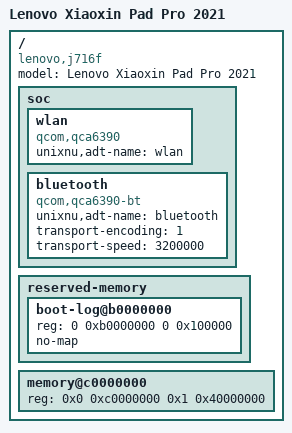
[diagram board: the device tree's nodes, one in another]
// SPDX-License-Identifier: BSD-2-Clause-Patent
// Board-level hardware description for Lenovo TB-J716F.
/dts-v1/;
/include/ "sm8250.dtsi"

/ {
    model = "Lenovo Xiaoxin Pad Pro 2021";
    compatible = "lenovo,j716f", "qcom,kona";

    // Export the radios under /soc (/arm-io in ADT) before launchd evaluates wifid's device-tree condition.
    // WifiProbe owns PCIe0 resources and fills local-mac-address at runtime.
    soc {
        wlan {
            compatible = "qcom,qca6390";
            unixnu,adt-name = "wlan";
            status = "okay";
        };

        bluetooth {
            device_type = "bluetooth";
            compatible = "qcom,qca6390-bt";
            unixnu,adt-name = "bluetooth";
            transport-encoding = <1>;
            transport-speed = <3200000>;
            status = "okay";
        };
    };

    // Existing ZUI/UEFI reservation; not an allocator extension or new partition.
    // Only console 0xb00be000+0x40000 is under review for native diagnostics.
    // Do not export the whole reservation as an arm-io device/MMIO alias.
    reserved-memory {
        #address-cells = <2>;
        #size-cells = <2>;
        ranges;
        boot-log@b0000000 {
            reg = <0 0xb0000000 0 0x100000>;
            no-map;
        };
    };

    memory@c0000000 {
        device_type = "memory";
        // Root DRAM describes capacity, not an arm-io MMIO device.
        reg = <0x0 0xc0000000 0x1 0x40000000>;
        status = "okay";
    };
};
